# PIC32CX0525SG12084 register map
Vendor: Microchip Technology; Series: 0525SG12; File version: 0
CPU: CM4 r1p0, little endian, no MPU, no FPU, 3 interrupt priority bits, 172 interrupts
Registers are 32-bit, read-write, reset 0x0 unless marked. A register's access mark holds for its fields unless they carry their own. Offsets are from the block's base; [hi:lo] are bit positions.

## HDMI_CEC — The HDMI-CEC provides high-level control functions between all the various audiovisual products in a users environment.
Base 0x40006800
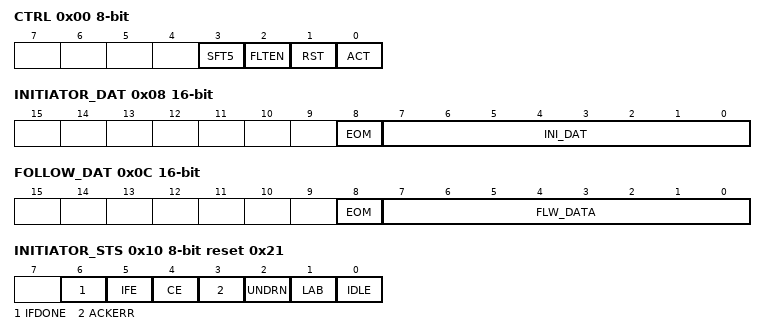
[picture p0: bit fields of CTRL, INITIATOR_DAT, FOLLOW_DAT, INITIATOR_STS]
0x00 CTRL 8-bit — HDMI CEC Control Register. Only bits [3:0] are used. Bits [31:4] are Reserved.
  [3] SFT5 — When this bit is written to '1', the Signal Free Time (SFT) is changed to '5' once only. This bit is cleared and normal SFT behavior resumes when the Bus Idle condition is asserted.
  [2] FLTEN — 1=Filtering on the CEC bus is enabled. 0=Filtering is disabled
  [1] RST — Soft reset the entire module. This bit is self-clearing.
  [0] ACT — Enable the blocks operation. (R/W). 1=The block is enabled for normal operation. 0=The block is disabled and placed in its lowest power state.
0x04 CLOG_ADDR 16-bit ro — HDMI CEC Claimed Logical Address Register. Only bits [15:0] are used. Bits [31:16] are Reserved.
  [15:0] ADDR — When any bit in this register is asserted ('1'), Follower Directed Messages and Follower Broadcast Messages addressed to that logical address are claimed by the Follower Interface. The Claimed Logical Address Register default effectively disables the Follower Interface.
0x08 INITIATOR_DAT 16-bit wo — HDMI CEC Initiator Data Register. Only bits [8:0] are used. Bits [31:9] are Reserved.
  [8] EOM — This bit is used for the End of Message bit in header/data blocks in CEC message frames. When the bit is '0' more data blocks follow; a '1' specifies that the message is complete. Reads of this field return 0.
  [7:0] INI_DAT — When any bit in this register is asserted ('1'), Follower Directed Messages and Follower Broadcast Messages addressed to that logical address are claimed by the Follower Interface. The Claimed Logical Address Register default effectively disables the Follower Interface. Reads of this field return 0.
0x0C FOLLOW_DAT 16-bit ro — HDMI CEC Follower Data Register. Only bits [8:0] are used. Bits [31:9] are Reserved.
  [8] EOM — This bit is the received End of Message bit from header/data blocks in CEC message frames. When the bit is '0' more data blocks follow; a '1' specifies that the message is complete.
  [7:0] FLW_DATA — This field is used for the received Information bits from header/data blocks in CEC message frames. Reads of this register when the FFNE bit in the Follower Status Register is not asserted ('0') return undefined data.
0x10 INITIATOR_STS 8-bit reset 0x21 — HDMI CEC Initiator Status Register. Only bits [6:0] are used. Bits [31:7] are Reserved.
  [6] IFDONE — The Initiator Frame Done bit is asserted ('1') when a message block with the EOM bit asserted ('1') has been transferred by the Initiator Interface, or the message frame has been terminated because an error occurred as defined by the LAB, UNDRN, ACKERR, and CE bits. R/WC.
  [5] IFE — The Initiator FIFO Empty bit is asserted ('1') when the Initiator Interface retrieves the last data entry from the FIFO.
  [4] CE — The Contention Error bit is asserted ('1') when bus contention is detected by the Initiator Interface at any point following CEC line arbitration. This is likely to be a consequence of CEC Line Error Handling (see CEC 7.4, CEC Line Error Handling in References [1]). R/WC.
  [3] ACKERR — The Acknowledge Error bit is asserted ('1') when the follower NACKs an acknowledge bit, both for Follower Directed Messages and Follower Broadcast Messages. For example, in Follower Directed Messages if the follower acknowledge bit response is '1' this bit is '1' in Follower Broadcast Messages if a follower acknowledge bit response is '0' the bit is '1'.
  [2] UNDRN — Initiator Underrun (UNDRN) 1=The Initiator shift register requires data from the Initiator Interface FIFO and the IFE bit is asserted. 0=No underrun detected. R/WC.
  [1] LAB — Lost Arbitration (LAB). 1=Bus contention is detected by the Initiator Interface during CEC line arbitration. 0=No bus contention detected. R/WC.
  [0] IDLE — 1=The CEC bus is idle. 0=The CEC bus is busy.
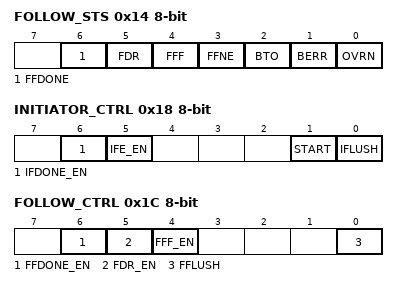
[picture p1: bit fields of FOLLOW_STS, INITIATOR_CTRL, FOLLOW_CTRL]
0x14 FOLLOW_STS 8-bit — HDMI CEC Follower Status Register. Only bits [6:0] are used. Bits [31:7] are Reserved.
  [6] FFDONE — The Follower Frame Done bit is asserted ('1') when a message block with the EOM bit asserted ('1') has been received by the Follower Interface, or the message frame has been terminated because an error occurred as defined by the OVRN, BERR, and BTO bits. R/WC.
  [5] FDR — The Follower Data Ready bit is asserted ('1') whenever received data is written to the Follower Interface FIFO. R/WC.
  [4] FFF — The Follower FIFO Full bit is asserted ('1') when there is no room in the Follower Interface FIFO for more data.
  [3] FFNE — The Follower FIFO Not Empty bit is asserted ('1') when there is data in the Follower Interface FIFO. The bit is not asserted ('0') when the Follower Interface FIFO is empty.
  [2] BTO — The Bus Time Out Detected bit is asserted ('1') when the follower detects that the CEC Bus is held high too long R/WC.
  [1] BERR — The Bus Error Detected bit is asserted ('1') when the follower detects spurious pulses on the CEC Bus. R/WC.
  [0] OVRN — The Follower Overrun bit is asserted ('1') when data from the follower shift register is transferred to the Follower Interface FIFO when the FFF bit is asserted. R/WC.
0x18 INITIATOR_CTRL 8-bit — HDMI CEC Initiator Control Register. Only bits [6:0] are used. Bits [31:7] are Reserved.
  [6] IFDONE_EN — Enable bit for the IFDONE interrupt. 1=Interrupt is enabled with IFDONE is asserted 0=Interrupt is disabled R/WC.
  [5] IFE_EN — Enable bit for the IFE interrupt. 1=Interrupt is enabled with IFE is asserted 0=Interrupt is disabled R/WC.
  [1] START — When this bit is asserted ('1'), the Initiator Interface begins a message frame transfer if the IFE bit is not asserted. If the Initiator Interface FIFO is empty when this bit is asserted, the message frame transfer begins as soon as a write to the Initiator Data Register occurs. In both cases, the bit is automatically cleared by hardware within one register access cycle. The START bit only needs to be asserted once per message frame. R/WC.
  [0] IFLUSH — When this bit is asserted ('1'), data in the Initiator Interface FIFO is cleared. When set, the bit is automatically cleared by hardware within one register access cycle. This bit can be used to terminate an Initiator Interface message frame transfer. R/WC.
0x1C FOLLOW_CTRL 8-bit — HDMI CEC Follower Control Register. Only bits [6:0] are used. Bits [31:7] are Reserved.
  [6] FFDONE_EN — Enable bit for the FFDONE interrupt. 1=Interrupt is enabled with FFDONE is asserted 0=Interrupt is disabled R/WC.
  [5] FDR_EN — Enable bit for the FDR interrupt. 1=Interrupt is enabled with FDR is asserted 0=Interrupt is disabled R/WC.
  [4] FFF_EN — Enable bit for the FFF interrupt. 1=Interrupt is enabled with FFF is asserted 0=Interrupt is disabled R/WC.
  [0] FFLUSH — When this bit is asserted ('1'), data in the Follower Interface FIFO is cleared. When set, the bit is automatically cleared by hardware within one register access cycle. R/WC.
0x20 CLK_DIV reset 0x1E0 — HDMI CEC Clock Divier Register. Reset value of this reister is 0x01E0.
  [31:0] CLK_DIV — HDMI CEC Clock Divier Register.
